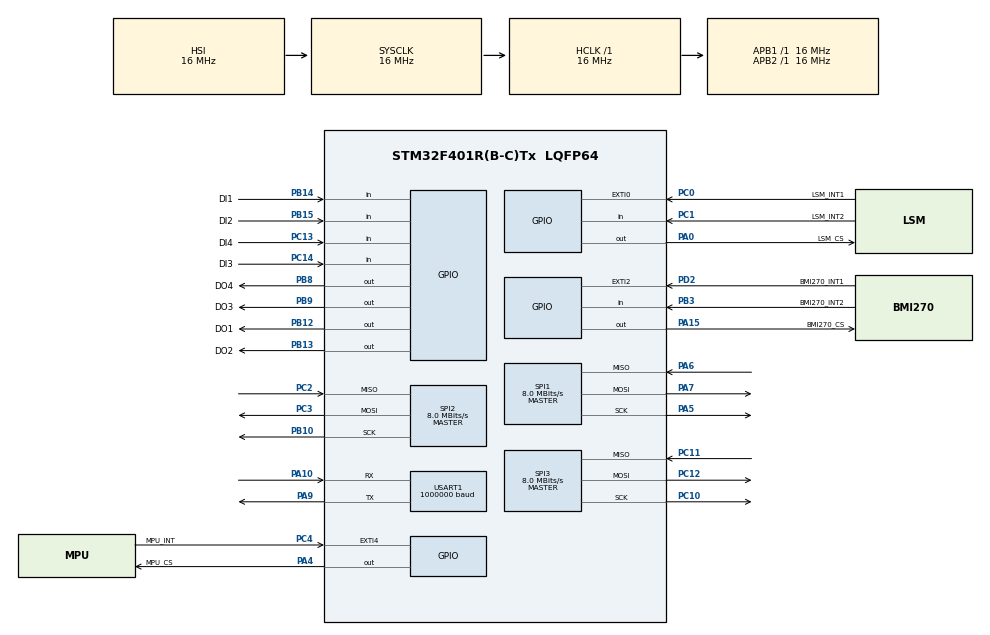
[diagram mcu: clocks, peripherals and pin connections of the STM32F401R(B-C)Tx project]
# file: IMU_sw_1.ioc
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FREERTOS.Tasks01=defaultTask,24,128,StartDefaultTask,Default,NULL,Dynamic,NULL,NULL
FREERTOS.configUSE_NEWLIB_REENTRANT=1
Mcu.Family=STM32F4
Mcu.Name=STM32F401R(B-C)Tx
Mcu.Package=LQFP64
NVIC.EXTI0_IRQn=true\:5\:0\:true\:false\:true\:false\:true\:true\:true
NVIC.EXTI2_IRQn=true\:5\:0\:true\:false\:true\:false\:true\:true\:true
NVIC.EXTI4_IRQn=true\:5\:0\:true\:false\:true\:false\:true\:true\:true
NVIC.PriorityGroup=NVIC_PRIORITYGROUP_4
NVIC.TIM1_UP_TIM10_IRQn=true\:4\:0\:true\:false\:true\:false\:false\:true\:true
NVIC.TimeBase=TIM1_UP_TIM10_IRQn
NVIC.TimeBaseIP=TIM1
PA0-WKUP.GPIO_Label=LSM_CS
PA0-WKUP.PinState=GPIO_PIN_SET
PA0-WKUP.Signal=GPIO_Output
PA10.Mode=Asynchronous
PA10.Signal=USART1_RX
PA13.Mode=Serial_Wire
PA13.Signal=SYS_JTMS-SWDIO
PA14.Mode=Serial_Wire
PA14.Signal=SYS_JTCK-SWCLK
PA15.GPIO_Label=BMI270_CS
PA15.PinState=GPIO_PIN_SET
PA15.Signal=GPIO_Output
PA4.GPIO_Label=MPU_CS
PA4.PinState=GPIO_PIN_SET
PA4.Signal=GPIO_Output
PA5.Mode=Full_Duplex_Master
PA5.Signal=SPI1_SCK
PA6.Mode=Full_Duplex_Master
PA6.Signal=SPI1_MISO
PA7.Mode=Full_Duplex_Master
PA7.Signal=SPI1_MOSI
PA9.Mode=Asynchronous
PA9.Signal=USART1_TX
PB10.Mode=Full_Duplex_Master
PB10.Signal=SPI2_SCK
PB12.GPIO_Label=DO1
PB12.Signal=GPIO_Output
PB13.GPIO_Label=DO2
PB13.Signal=GPIO_Output
PB14.GPIO_Label=DI1
PB14.Signal=GPIO_Input
PB15.GPIO_Label=DI2
PB15.Signal=GPIO_Input
PB3.GPIO_Label=BMI270_INT2
PB3.Signal=GPIO_Input
PB8.GPIO_Label=DO4
PB8.Signal=GPIO_Output
PB9.GPIO_Label=DO3
PB9.Signal=GPIO_Output
PC0.GPIO_Label=LSM_INT1
PC0.Signal=GPXTI0
PC1.GPIO_Label=LSM_INT2
PC1.Signal=GPIO_Input
PC10.Mode=Full_Duplex_Master
PC10.Signal=SPI3_SCK
PC11.Mode=Full_Duplex_Master
PC11.Signal=SPI3_MISO
PC12.Mode=Full_Duplex_Master
PC12.Signal=SPI3_MOSI
PC13-ANTI_TAMP.GPIO_Label=DI4
PC13-ANTI_TAMP.Signal=GPIO_Input
PC14-OSC32_IN.GPIO_Label=DI3
PC14-OSC32_IN.Signal=GPIO_Input
PC2.Mode=Full_Duplex_Master
PC2.Signal=SPI2_MISO
PC3.Mode=Full_Duplex_Master
PC3.Signal=SPI2_MOSI
PC4.GPIO_Label=MPU_INT
PC4.Signal=GPXTI4
PD2.GPIO_Label=BMI270_INT1
PD2.Signal=GPXTI2
PH0\ -\ OSC_IN.Mode=HSE-External-Oscillator
PH0\ -\ OSC_IN.Signal=RCC_OSC_IN
PH1\ -\ OSC_OUT.Mode=HSE-External-Oscillator
PH1\ -\ OSC_OUT.Signal=RCC_OSC_OUT
ProjectManager.HeapSize=0x200
ProjectManager.StackSize=0x400
ProjectManager.TargetToolchain=CMake
RCC.AHBFreq_Value=16000000
RCC.APB1Freq_Value=16000000
RCC.APB2Freq_Value=16000000
RCC.CortexFreq_Value=16000000
RCC.HSE_VALUE=25000000
RCC.HSI_VALUE=16000000
RCC.LSE_VALUE=32768
RCC.SYSCLKFreq_VALUE=16000000
RCC.VCOOutputFreq_Value=192000000
SPI1.CLKPhase=SPI_PHASE_2EDGE
SPI1.CLKPolarity=SPI_POLARITY_HIGH
SPI1.CalculateBaudRate=8.0 MBits/s
SPI1.Direction=SPI_DIRECTION_2LINES
SPI1.Mode=SPI_MODE_MASTER
SPI1.VirtualType=VM_MASTER
SPI2.BaudRatePrescaler=SPI_BAUDRATEPRESCALER_2
SPI2.CLKPhase=SPI_PHASE_2EDGE
SPI2.CLKPolarity=SPI_POLARITY_HIGH
SPI2.CalculateBaudRate=8.0 MBits/s
SPI2.Direction=SPI_DIRECTION_2LINES
SPI2.Mode=SPI_MODE_MASTER
SPI2.VirtualType=VM_MASTER
SPI3.CLKPhase=SPI_PHASE_2EDGE
SPI3.CLKPolarity=SPI_POLARITY_HIGH
SPI3.CalculateBaudRate=8.0 MBits/s
SPI3.Direction=SPI_DIRECTION_2LINES
SPI3.Mode=SPI_MODE_MASTER
SPI3.VirtualType=VM_MASTER
USART1.BaudRate=1000000
USART1.VirtualMode=VM_ASYNC
VP_FREERTOS_VS_CMSIS_V2.Mode=CMSIS_V2
VP_SYS_VS_tim1.Mode=TIM1
board=custom

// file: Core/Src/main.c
/* USER CODE BEGIN Header */
/**
  ******************************************************************************
  * @file           : main.c
  * @brief          : Main program body
  ******************************************************************************
  * @attention
  *
  * Copyright (c) 2026 STMicroelectronics.
  * All rights reserved.
  *
  * This software is licensed under terms that can be found in the LICENSE file
  * in the root directory of this software component.
  * If no LICENSE file comes with this software, it is provided AS-IS.
  *
  ******************************************************************************
  */
/* USER CODE END Header */
#include "main.h"
#include "cmsis_os.h"
#include "spi.h"
#include "usart.h"
#include "gpio.h"

/* USER CODE BEGIN Includes */
#include "Task_IMU.h"
#include "filter_task.h"
#include "uart_task.h"
/* USER CODE END Includes */

/* USER CODE BEGIN PV */
/* Task_IMU/Task_Filter/Task_UART создаются через свой Start() на сыром
 * FreeRTOS API (xTaskCreate) — см. USER CODE RTOS_THREADS ниже. */
/* USER CODE END PV */

void SystemClock_Config(void);
void MX_FREERTOS_Init(void);

int main(void)
{

  /* MCU Configuration--------------------------------------------------------*/

  /* Reset of all peripherals, Initializes the Flash interface and the Systick. */
  HAL_Init();

  /* Configure the system clock */
  SystemClock_Config();

  /* Initialize all configured peripherals */
  MX_GPIO_Init();
  MX_SPI1_Init();
  MX_SPI2_Init();
  MX_SPI3_Init();
  MX_USART1_UART_Init();
  /* USER CODE BEGIN 2 */
  Task_Filter_Start();
  Task_IMU_Start();
  Task_UART_Start();
  /* USER CODE END 2 */

  /* Init scheduler */
  osKernelInitialize();  /* Call init function for freertos objects (in cmsis_os2.c) */
  MX_FREERTOS_Init();

  /* Start scheduler */
  osKernelStart();

  /* We should never get here as control is now taken by the scheduler */

  /* Infinite loop */
  while (1)
  {

  }
}

void SystemClock_Config(void)
{
  RCC_OscInitTypeDef RCC_OscInitStruct = {0};
  RCC_ClkInitTypeDef RCC_ClkInitStruct = {0};

  /** Configure the main internal regulator output voltage
  */
  __HAL_RCC_PWR_CLK_ENABLE();
  __HAL_PWR_VOLTAGESCALING_CONFIG(PWR_REGULATOR_VOLTAGE_SCALE2);

  /** Initializes the RCC Oscillators according to the specified parameters
  * in the RCC_OscInitTypeDef structure.
  */
  RCC_OscInitStruct.OscillatorType = RCC_OSCILLATORTYPE_HSI;
  RCC_OscInitStruct.HSIState = RCC_HSI_ON;
  RCC_OscInitStruct.HSICalibrationValue = RCC_HSICALIBRATION_DEFAULT;
  RCC_OscInitStruct.PLL.PLLState = RCC_PLL_NONE;
  if (HAL_RCC_OscConfig(&RCC_OscInitStruct) != HAL_OK)
  {
    Error_Handler();
  }

  /** Initializes the CPU, AHB and APB buses clocks
  */
  RCC_ClkInitStruct.ClockType = RCC_CLOCKTYPE_HCLK|RCC_CLOCKTYPE_SYSCLK
                              |RCC_CLOCKTYPE_PCLK1|RCC_CLOCKTYPE_PCLK2;
  RCC_ClkInitStruct.SYSCLKSource = RCC_SYSCLKSOURCE_HSI;
  RCC_ClkInitStruct.AHBCLKDivider = RCC_SYSCLK_DIV1;
  RCC_ClkInitStruct.APB1CLKDivider = RCC_HCLK_DIV1;
  RCC_ClkInitStruct.APB2CLKDivider = RCC_HCLK_DIV1;

  if (HAL_RCC_ClockConfig(&RCC_ClkInitStruct, FLASH_LATENCY_0) != HAL_OK)
  {
    Error_Handler();
  }
}

/* USER CODE BEGIN 4 */
/* Опрос датчиков теперь поллингом из Task_IMU (см. Tasks/IMU_task/Task_IMU.c),
 * EXTI-callback больше не используется. Пины LSM_INT1/BMI270_INT1/MPU_INT
 * остаются настроены как EXTI в CubeMX — это безвредно (событие просто не
 * обрабатывается), при желании можно вернуть их в обычный GPIO_Input. */
/* USER CODE END 4 */

void HAL_TIM_PeriodElapsedCallback(TIM_HandleTypeDef *htim)
{
  if (htim->Instance == TIM1)
  {
    HAL_IncTick();
  }
}

void Error_Handler(void)
{
  __disable_irq();
  while (1)
  {
  }
}
